# NUC1311AE_v1 register map
File version: 1.0
Registers are 32-bit, read-write, reset 0x0 unless marked. A register's access mark holds for its fields unless they carry their own. Offsets are from the block's base; [hi:lo] are bit positions; {n}, {i} and the like mark numbered series; 'fields as' and 'values as' point back to an identical list.

## INT — INT Register Map
Base 0x50000300
0x00 IRQ0_SRC ro reset not defined — IRQ0 (BOD) Interrupt Source Identity
  [3:0] INT_SRC — Interrupt Source. Define the interrupt sources for interrupt event.
0x04 IRQ1_SRC ro reset not defined — IRQ1 (WDT) Interrupt Source Identity
  fields as IRQ0_SRC
0x08 IRQ2_SRC ro reset not defined — IRQ2 (EINT0) Interrupt Source Identity
  fields as IRQ0_SRC
0x0C IRQ3_SRC ro reset not defined — IRQ3 (EINT1) Interrupt Source Identity
  fields as IRQ0_SRC
0x10 IRQ4_SRC ro reset not defined — IRQ4 (GPA/B) Interrupt Source Identity
  fields as IRQ0_SRC
0x14 IRQ5_SRC ro reset not defined — IRQ5 (GPC/D/E/F) Interrupt Source Identity
  fields as IRQ0_SRC
0x18 IRQ6_SRC ro reset not defined — Reserved.
  fields as IRQ0_SRC
0x1C IRQ7_SRC ro reset not defined — Reserved.
  fields as IRQ0_SRC
{0x0+4i} IRQ{i}_SRC ro reset not defined (i=8..11) — IRQ{i} (TMR{i-8}) Interrupt Source Identity
  fields as IRQ0_SRC
0x30 IRQ12_SRC ro reset not defined — IRQ12 (UART0/2) Interrupt Source Identity
  fields as IRQ0_SRC
0x34 IRQ13_SRC ro reset not defined — IRQ13 (UART1) Interrupt Source Identity
  fields as IRQ0_SRC
0x38 IRQ14_SRC ro reset not defined — IRQ14 (SPI0) Interrupt Source Identity
  fields as IRQ0_SRC
{0x0+4i} IRQ{i}_SRC ro reset not defined (i=15..17) — IRQ{i} (UART{i-12}) Interrupt Source Identity
  fields as IRQ0_SRC
0x48 IRQ18_SRC ro reset not defined — IRQ18 (I2C0) Interrupt Source Identity
  fields as IRQ0_SRC
0x4C IRQ19_SRC ro reset not defined — IRQ19 (I2C1) Interrupt Source Identity
  fields as IRQ0_SRC
0x50 IRQ20_SRC ro reset not defined — IRQ20 (CAN0) Interrupt Source Identity
  fields as IRQ0_SRC
0x54 IRQ21_SRC ro reset not defined — Reserved.
  fields as IRQ0_SRC
0x58 IRQ22_SRC ro reset not defined — IRQ22 (PWM0) Interrupt Source Identity
  fields as IRQ0_SRC
0x5C IRQ23_SRC ro reset not defined — IRQ23 (PWM1) Interrupt Source Identity
  fields as IRQ0_SRC
0x60 IRQ24_SRC ro reset not defined — IRQ24 (BPWM0) Interrupt Source Identity
  fields as IRQ0_SRC
0x64 IRQ25_SRC ro reset not defined — IRQ25 (BPWM1) Interrupt Source Identity
  fields as IRQ0_SRC
0x68 IRQ26_SRC ro reset not defined — IRQ26 (BRAKE0) Interrupt Source Identity
  fields as IRQ0_SRC
0x6C IRQ27_SRC ro reset not defined — IRQ27 (BRAKE1) Interrupt Source Identity
  fields as IRQ0_SRC
0x70 IRQ28_SRC ro reset not defined — IRQ28 (PWRWU) Interrupt Source Identity
  fields as IRQ0_SRC
0x74 IRQ29_SRC ro reset not defined — IRQ29 (ADC) Interrupt Source Identity
  fields as IRQ0_SRC
0x78 IRQ30_SRC ro reset not defined — IRQ30 (CKD) Interrupt Source Identity
  fields as IRQ0_SRC
0x7C IRQ31_SRC ro reset not defined — Reserved.
  fields as IRQ0_SRC
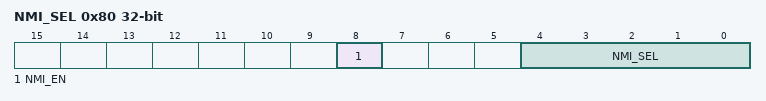
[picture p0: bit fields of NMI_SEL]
0x80 NMI_SEL — NMI Source Interrupt Select Control Register
  [8] NMI_EN — NMI Interrupt Enable Control (Write Protect). Note: This bit is the protected bit, and programming it needs to write '59h', '16h', and '88h' to address 0x5000_0100 to disable register protection. Refer to the register REGWRPROT at address GCR_BA+0x100.
    0=NMI interrupt Disabled; 1=NMI interrupt Enabled
  [4:0] NMI_SEL — NMI Interrupt Source Selection. The NMI interrupt to Cortex-M0 can be selected from one of the peripheral interrupt by setting NMI_SEL.
0x84 MCU_IRQ — MCU Interrupt Request Source Register
  [31:0] MCU_IRQ — MCU IRQ Source Register. The MCU_IRQ collects all the interrupts from the peripherals and generates the synchronous interrupt to Cortex-M0. There are two modes to generate interrupt to Cortex-M0, the normal mode and test mode. The MCU_IRQ collects all interrupts from each peripheral and synchronizes them and interrupts the Cortex-M0. When the MCU_IRQ[n] is 0: Set MCU_IRQ[n] 1 will generate an interrupt to Cortex-M0 NVIC[n]. When the MCU_IRQ[n] is 1 (mean an interrupt is assert), setting 1 to the MCU_IRQ[n] 1 will clear the interrupt and setting MCU_IRQ[n] 0: has no effect.
0x88 MCU_IRQCR — MCU Interrupt Request Control Register
  [0] FAST_IRQ — Fast IRQ Latency Enable Control
    0=MCU IRQ latency is fixed at 13 clock cycles of HCLK, MCU will enter IRQ handler after this fixed latency when interrupt happened; 1=MCU IRQ latency will not fixed, MCU will enter IRQ handler as soon as possible when interrupt happened
